# MB9AF13xK register map
File version: 1.7
CPU: 
Registers are 8-bit, read-write, reset 0x0 unless marked. A register's access mark holds for its fields unless they carry their own. Offsets are from the block's base; [hi:lo] are bit positions; {n}, {i} and the like mark numbered series.

## MFT_PPG — PPG Configuration
Base 0x40024000
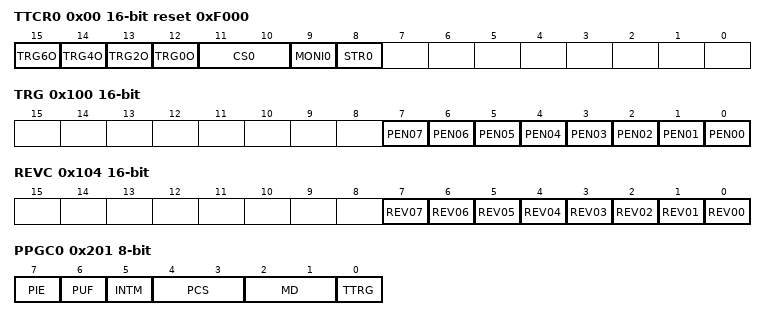
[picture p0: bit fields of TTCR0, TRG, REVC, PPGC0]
0x00 TTCR0 16-bit reset 0xF000 — PPG Start Trigger Control Register 0
  [15] TRG6O — PPG6 trigger stop bit
  [14] TRG4O — PPG4 trigger stop bit
  [13] TRG2O — PPG2 trigger stop bit
  [12] TRG0O — PPG0 trigger stop bit
  [11:10] CS0 — 8-bit UP counter clock select bits for comparison
  [9] MONI0 ro — 8-bit UP counter operation state monitor bit for comparison
  [8] STR0 — 8-bit UP counter operation enable bit for comparison
0x08 COMP0 16-bit (reset mask 0xFF00) — PPG Compare Register 0
0x0C COMP2 — PPG Compare Register 2
0x10 COMP4 32-bit reset not defined — PPG Compare Register 4
0x14 COMP6 32-bit reset not defined — PPG Compare Register 6
0x100 TRG 16-bit — PPG Start Register 0
  [n] PEN{n:02} (n=0..7) — PPG{n} Start Trigger bit
0x104 REVC 16-bit — Output Reverse Register 0
  [n] REV{n:02} (n=0..7) — PPG{n} Output Reverse Enable bit
0x200 PPGC1 32-bit reset not defined — PPG Operation Mode Control Register 1
0x201 PPGC0 — PPG Operation Mode Control Register 0
  [7] PIE — PPG Interrupt Enable bit
  [6] PUF — PPG Counter Underflow bit
  [5] INTM — Interrupt Mode Select bit
  [4:3] PCS — PPG DOWN Counter Operation Clock Select bits
  [2:1] MD — PPG Operation Mode Set bits
  [0] TTRG — PPG start trigger select bit
0x204 PPGC3 32-bit reset not defined — PPG Operation Mode Control Register 3
0x205 PPGC2 32-bit reset not defined — PPG Operation Mode Control Register 2
0x208 PRLL0 reset not defined — PPG0 Reload Registers Low
  [7:0] PRLL — Reload Registers Low
0x209 PRLH0 reset not defined — PPG0 Reload Registers High
  [7:0] PRLH — Reload Registers High
{0x208+4i} PRLL{i} 32-bit reset not defined (i=1..3) — PPG{i} Reload Registers Low
{0x209+4i} PRLH{i} 32-bit reset not defined (i=1..3) — PPG{i} Reload Registers High
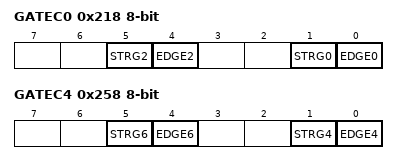
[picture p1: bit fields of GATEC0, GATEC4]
0x218 GATEC0 — PPG Gate Function Control Registers 0
  [5] STRG2 — Select a trigger for PPG2
  [4] EDGE2 — Select Start Effective Level for PPG2
  [1] STRG0 — Select a trigger for PPG0
  [0] EDGE0 — Select Start Effective Level for PPG0
0x240 PPGC5 32-bit reset not defined — PPG Operation Mode Control Register 5
0x241 PPGC4 32-bit reset not defined — PPG Operation Mode Control Register 4
0x244 PPGC7 32-bit reset not defined — PPG Operation Mode Control Register 7
0x245 PPGC6 32-bit reset not defined — PPG Operation Mode Control Register 6
{0x238+4i} PRLL{i} 32-bit reset not defined (i=4..7) — PPG{i} Reload Registers Low
{0x239+4i} PRLH{i} 32-bit reset not defined (i=4..7) — PPG{i} Reload Registers High
0x258 GATEC4 — PPG Gate Function Control Registers 4
  [5] STRG6 — Select a trigger for PPG6
  [4] EDGE6 — Select Start Effective Level for PPG6
  [1] STRG4 — Select a trigger for PPG4
  [0] EDGE4 — Select Start Effective Level for PPG4

## EXTI — External Interrupt and NMI Control
Base 0x40030000
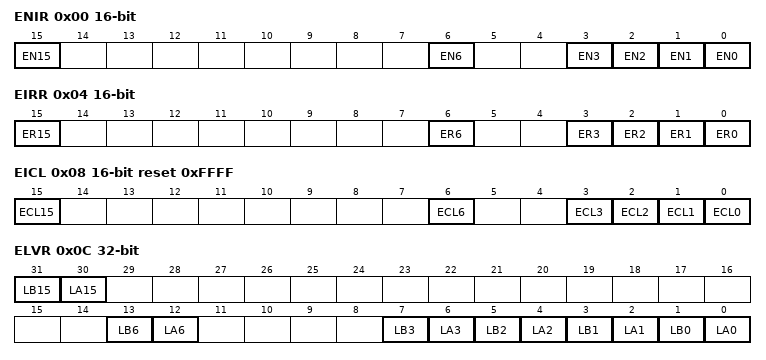
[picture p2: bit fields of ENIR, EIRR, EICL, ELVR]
0x00 ENIR 16-bit — Enable Interrupt Request Register
  [15] EN15 — Bit15 of ENIR
  [6] EN6 — Bit6 of ENIR
  [n] EN{n} (n=0..3) — Bit{n} of ENIR
0x04 EIRR 16-bit ro reset not defined — External Interrupt Request Register
  [15] ER15 — Bit15 of EIRR
  [6] ER6 — Bit6 of EIRR
  [n] ER{n} (n=0..3) — Bit{n} of EIRR
0x08 EICL 16-bit reset 0xFFFF — External Interrupt Clear Register
  [15] ECL15 — Bit15 of EICL
  [6] ECL6 — Bit6 of EICL
  [n] ECL{n} (n=0..3) — Bit{n} of EICL
0x0C ELVR 32-bit — External Interrupt Level Register
  [31] LB15 — Bit31 of ELVR
  [30] LA15 — Bit30 of ELVR
  [13] LB6 — Bit13 of ELVR
  [12] LA6 — Bit12 of ELVR
  [2n+1] LB{n} (n=0..3) — Bit{2n+1} of ELVR
  [2n] LA{n} (n=0..3) — Bit{2n} of ELVR
0x14 NMIRR ro — Non Maskable Interrupt Request Register
  [0] NR — NMI interrupt request detection bit
0x18 NMICL reset 0x1 — Non Maskable Interrupt Clear Register
  [0] NCL — NMI interrupt cause clear bit

## LVD — Low-voltage Detection
Base 0x40035000
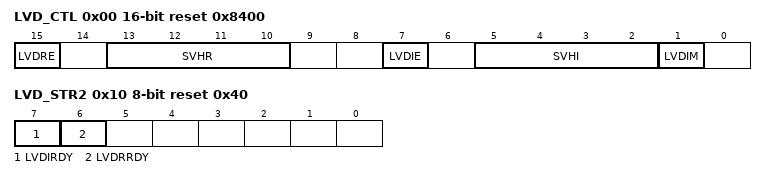
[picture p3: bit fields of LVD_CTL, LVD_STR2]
0x00 LVD_CTL 16-bit reset 0x8400 — Low-voltage Detection Voltage Control Register
  [15] LVDRE — Low-voltage detection reset operation enable bit
  [13:10] SVHR — Low-voltage detection reset voltage setting bits
  [7] LVDIE — Low-voltage detection interrupt enable bit
  [5:2] SVHI — Low-voltage detection interrupt voltage setting bits
  [1] LVDIM — Low-voltage detection interrupt low power mode select bit
0x04 LVD_STR ro — Low-voltage Detection Interrupt Register
  [7] LVDIR — Low-voltage detection interrupt bit
0x08 LVD_CLR reset 0x80 — Low-voltage Detection Interrupt Clear Register
  [7] LVDCL — Low-voltage detection interrupt clear bit
0x0C LVD_RLR 32-bit reset 0x1 — Low-voltage Detection Voltage Protection Register
  [31:0] LVDLCK — Low-voltage Detection Voltage Control Register protection bits
0x10 LVD_STR2 ro reset 0x40 — Low-voltage Detection Circuit Status Register
  [7] LVDIRDY — Low-voltage detection interrupt status flag
  [6] LVDRRDY — Low-voltage detection reset status flag

## DS — Low Power Consumption Mode
Base 0x40035800
0x00 PMD_CTL — RTC Mode Control Register
  [0] RTCE — RTC mode control bit
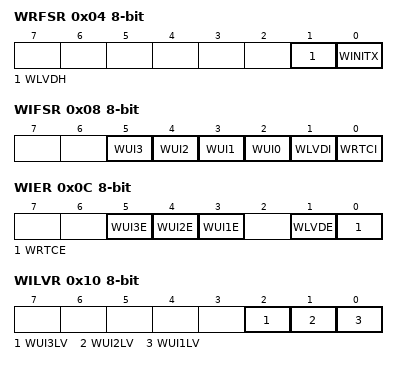
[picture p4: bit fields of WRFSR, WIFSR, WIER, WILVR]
0x04 WRFSR — Deep Standby Return Cause Register 1
  [1] WLVDH — Low-voltage detection reset return bit
  [0] WINITX — INITX pin input reset return bit
0x08 WIFSR ro — Deep Standby Return Cause Register 2
  [n+2] WUI{n} (n=0..3) — WKUP pin input return bit {n}
  [1] WLVDI — LVD interrupt return bit
  [0] WRTCI — RTC interrupt return bit
0x0C WIER — Deep Standby Return Enable Register
  [5] WUI3E — WKUP pin input return enable bit 3
  [4] WUI2E — WKUP pin input return enable bit 2
  [3] WUI1E — WKUP pin input return enable bit 1
  [1] WLVDE — LVD interrupt return enable bit
  [0] WRTCE — RTC interrupt return enable bit
0x10 WILVR — WKUP Pin Input Level Register
  [2] WUI3LV — WKUP pin input level select bit 3
  [1] WUI2LV — WKUP pin input level select bit 2
  [0] WUI1LV — WKUP pin input level select bit 1
{0xFF+i} BUR{i:02} (i=1..16) — Backup Registers from {i}
